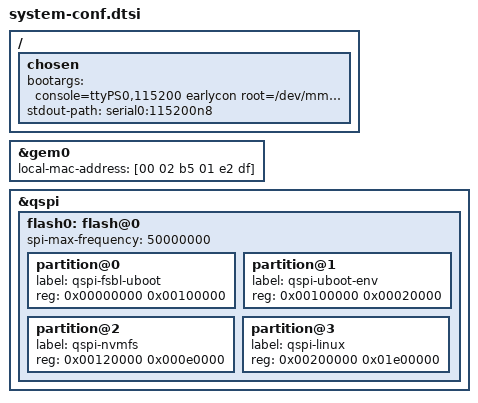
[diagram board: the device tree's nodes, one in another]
/*
 * CAUTION: This file is automatically generated by PetaLinux SDK.
 * DO NOT modify this file
 */


/ {
	chosen {
		bootargs = "console=ttyPS0,115200 earlycon root=/dev/mmcblk0p2 rw rootwait";
		stdout-path = "serial0:115200n8";
	};
};

&gem0 {
	local-mac-address = [00 02 b5 01 e2 df];
};

&qspi {
	#address-cells = <1>;
	#size-cells = <0>;
	flash0: flash@0 {
		spi-max-frequency = <50000000>;
		partition@0 {
			label = "qspi-fsbl-uboot";
			reg = <0x00000000 0x00100000>;
		};
		partition@1 {
			label = "qspi-uboot-env";
			reg = <0x00100000 0x00020000>;
		};
		partition@2 {
			label = "qspi-nvmfs";
			reg = <0x00120000 0x000e0000>;
		};
		partition@3 {
			label = "qspi-linux";
			reg = <0x00200000 0x01e00000>;
		};
	};
};

